VERSION "HIPBNYYYYYYYYYYYYYYYYYYYYYYYYYYYYYYYYYYYYY/4/%%%/4/'%**4YYY///"

NS_ :

BS_:

BU_:

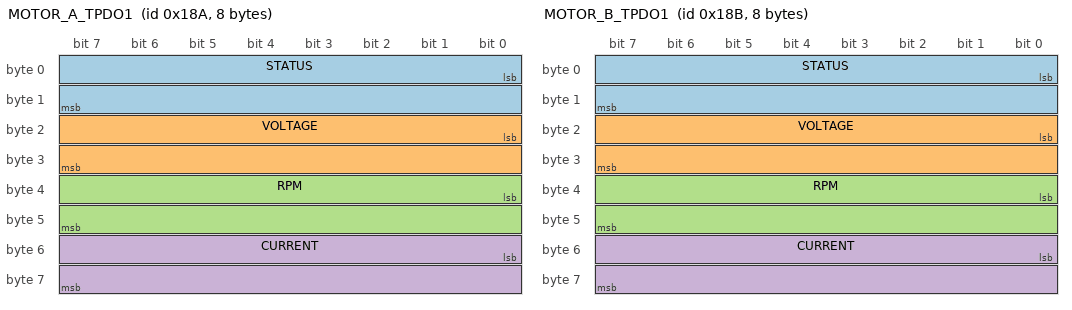
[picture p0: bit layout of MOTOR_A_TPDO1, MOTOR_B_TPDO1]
BO_ 394 MOTOR_A_TPDO1: 8 Vector__XXX
 SG_ STATUS M : 0|16@1+ (1,0) [0|0] "" Vector__XXX
 SG_ VOLTAGE : 16|16@1+ (32,0) [0|0] "MV" Vector__XXX
 SG_ RPM : 32|16@1- (1,0) [0|0] "RPM" Vector__XXX
 SG_ CURRENT : 48|16@1+ (32,0) [0|0] "MA" Vector__XXX

BO_ 395 MOTOR_B_TPDO1: 8 Vector__XXX
 SG_ STATUS M : 0|16@1+ (1,0) [0|0] "" Vector__XXX
 SG_ VOLTAGE : 16|16@1+ (32,0) [0|0] "MV" Vector__XXX
 SG_ RPM : 32|16@1- (1,0) [0|0] "RPM" Vector__XXX
 SG_ CURRENT : 48|16@1+ (32,0) [0|0] "MA" Vector__XXX

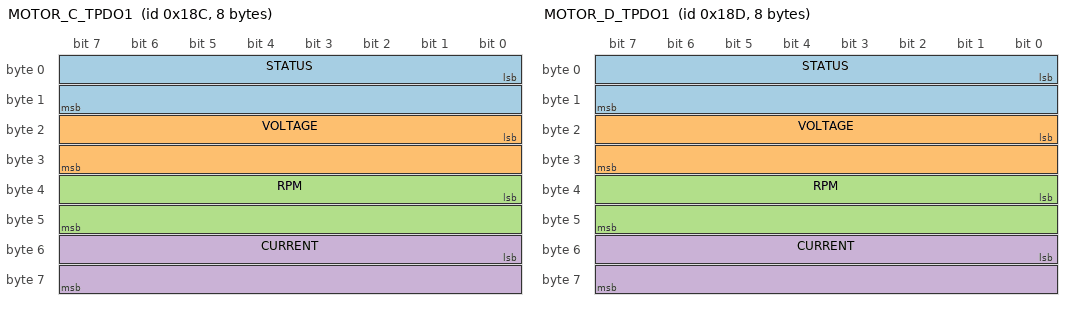
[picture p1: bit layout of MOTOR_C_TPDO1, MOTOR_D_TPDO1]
BO_ 396 MOTOR_C_TPDO1: 8 Vector__XXX
 SG_ STATUS M : 0|16@1+ (1,0) [0|0] "" Vector__XXX
 SG_ VOLTAGE : 16|16@1+ (32,0) [0|0] "MV" Vector__XXX
 SG_ RPM : 32|16@1- (1,0) [0|0] "RPM" Vector__XXX
 SG_ CURRENT : 48|16@1+ (32,0) [0|0] "MA" Vector__XXX

BO_ 397 MOTOR_D_TPDO1: 8 Vector__XXX
 SG_ STATUS M : 0|16@1+ (1,0) [0|0] "" Vector__XXX
 SG_ VOLTAGE : 16|16@1+ (32,0) [0|0] "MV" Vector__XXX
 SG_ RPM : 32|16@1- (1,0) [0|0] "RPM" Vector__XXX
 SG_ CURRENT : 48|16@1+ (32,0) [0|0] "MA" Vector__XXX

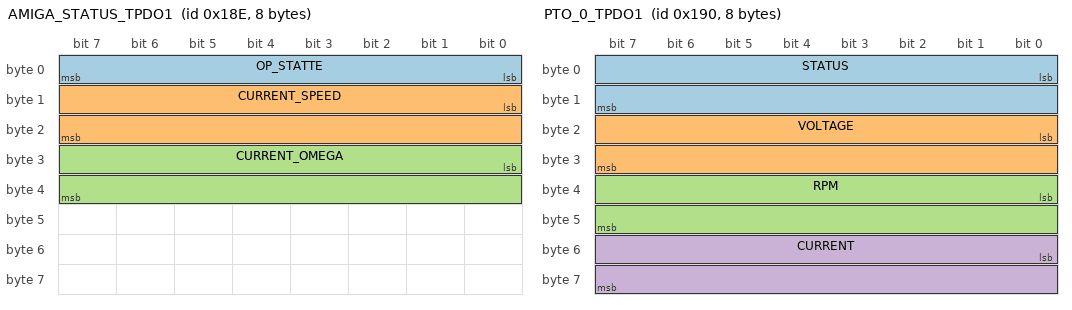
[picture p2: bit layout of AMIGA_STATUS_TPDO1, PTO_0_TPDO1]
BO_ 398 AMIGA_STATUS_TPDO1: 8 AmigaDashboard
 SG_ OP_STATTE : 0|8@1+ (1,0) [0|255] "" Vector__XXX
 SG_ CURRENT_SPEED : 8|16@1- (0.001,0) [-32.768|32.767] "mps" Vector__XXX
 SG_ CURRENT_OMEGA : 24|16@1- (0.001,0) [-32.768|32.767] "rad/ sec" Vector__XXX

BO_ 522 MOTOR_A_RPDO1: 8 Vector__XXX
 SG_ STATUS M : 0|16@1+ (1,0) [0|0] "" Vector__XXX
 SG_ RPM : 16|16@1- (1,0) [0|0] "RPM" Vector__XXX

BO_ 523 MOTOR_B_RPDO1: 8 Vector__XXX
 SG_ STATUS : 0|16@1+ (1,0) [0|0] "" Vector__XXX
 SG_ RPM : 16|16@1- (1,0) [0|0] "RPM" Vector__XXX

BO_ 524 MOTOR_C_RPDO1: 8 Vector__XXX
 SG_ STATUS M : 0|16@1+ (1,0) [0|0] "" Vector__XXX
 SG_ RPM : 16|16@1- (1,0) [0|0] "RPM" Vector__XXX

BO_ 525 MOTOR_D_RPDO1: 8 Vector__XXX
 SG_ STATUS M : 0|16@1+ (1,0) [0|0] "" Vector__XXX
 SG_ RPM : 16|16@1- (1,0) [0|0] "RPM" Vector__XXX

BO_ 1418 MOTOR_A_SDO: 8 Vector__XXX
 SG_ TEMP : 32|16@1- (1,0) [0|0] "C" Vector__XXX

BO_ 1419 MOTOR_B_SDO: 8 Vector__XXX
 SG_ TEMP : 32|16@1- (1,0) [0|0] "C" Vector__XXX

BO_ 1420 MOTOR_C_SDO: 8 Vector__XXX
 SG_ TEMP : 32|16@1- (1,0) [0|0] "C" Vector__XXX

BO_ 1421 MOTOR_D_SDO: 8 Vector__XXX
 SG_ TEMP : 32|16@1- (1,0) [0|0] "C" Vector__XXX

BO_ 400 PTO_0_TPDO1: 8 Vector__XXX
 SG_ STATUS M : 0|16@1+ (1,0) [0|0] "" Vector__XXX
 SG_ VOLTAGE : 16|16@1+ (32,0) [0|0] "MV" Vector__XXX
 SG_ RPM : 32|16@1- (1,0) [0|0] "RPM" Vector__XXX
 SG_ CURRENT : 48|16@1+ (32,0) [0|0] "MA" Vector__XXX

BO_ 528 PTO_0_RPDO1: 8 Vector__XXX
 SG_ STATUS M : 0|16@1+ (1,0) [0|0] "" Vector__XXX
 SG_ RPM : 16|16@1- (1,0) [0|0] "RPM" Vector__XXX

BO_ 650 MOTOR_A_TPDO2: 8 Vector__XXX
 SG_ MOTOR_POWER : 0|16@1- (1,0) [0|0] "" Vector__XXX
 SG_ BATT_POWER : 16|16@1- (1,0) [0|0] "" Vector__XXX

BO_ 651 MOTOR_B_TPDO2: 8 Vector__XXX
 SG_ MOTOR_POWER : 0|16@1- (32,0) [0|0] "" Vector__XXX
 SG_ BATT_POWER : 16|16@1- (1,0) [0|0] "" Vector__XXX

BO_ 652 MOTOR_C_TPDO2: 8 Vector__XXX
 SG_ MOTOR_POWER : 0|16@1- (32,0) [0|0] "" Vector__XXX
 SG_ BATT_POWER : 16|16@1- (1,0) [0|0] "" Vector__XXX

BO_ 653 MOTOR_D_TPDO2: 8 Vector__XXX
 SG_ MOTOR_POWER : 0|16@1- (32,0) [0|0] "" Vector__XXX
 SG_ BATT_POWER : 16|16@1- (1,0) [0|0] "" Vector__XXX

BO_ 399 PENDANT_TPDO1: 8 Vector__XXX
 SG_ X_POS : 0|16@1- (1,0) [0|0] "" Vector__XXX
 SG_ Y_POS : 16|16@1- (1,0) [0|0] "" Vector__XXX

BO_ 656 PTO_0_TPDO2: 8 Vector__XXX
 SG_ BATT_POWER : 0|16@1- (1,0) [0|0] "" Vector__XXX
 SG_ BATT_CURRENT : 16|16@1- (32,0) [0|0] "" Vector__XXX

CM_ BO_ 397 " ";
VAL_ 394 STATUS 0 "PRE-OP" 1 "IDLE" 2 "POST-OP" 3 "RUN" 4 "FAULT" ;
VAL_ 395 STATUS 0 "PRE-OP" 1 "IDLE" 2 "POST-OP" 3 "RUN" 4 "FAULT" ;
VAL_ 396 STATUS 0 "PRE-OP" 1 "IDLE" 2 "POST-OP" 3 "RUN" 4 "FAULT" ;
VAL_ 397 STATUS 0 "PRE-OP" 1 "IDLE" 2 "POST-OP" 3 "RUN" 4 "FAULT" ;
